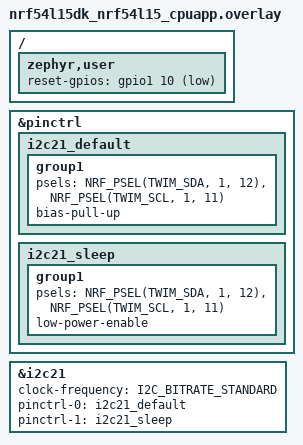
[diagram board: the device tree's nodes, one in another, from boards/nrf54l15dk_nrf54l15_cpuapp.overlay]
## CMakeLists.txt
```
cmake_minimum_required(VERSION 3.20.0)

find_package(Zephyr REQUIRED HINTS $ENV{ZEPHYR_BASE})
project(radar_central)

file(GLOB app_sources CONFIGURE_DEPENDS src/*.c)
target_sources(app PRIVATE ${app_sources})
target_include_directories(app PRIVATE include ../common)
```

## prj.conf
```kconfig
CONFIG_BT=y
CONFIG_BT_CENTRAL=y
CONFIG_BT_SMP=y
CONFIG_BT_BONDABLE=n
CONFIG_BT_CHANNEL_SOUNDING=y
CONFIG_BT_GAP_AUTO_UPDATE_CONN_PARAMS=n
CONFIG_BT_GATT_CLIENT=y
CONFIG_BT_GATT_AUTO_DISCOVER_CCC=y
CONFIG_BT_L2CAP_TX_MTU=498
CONFIG_BT_BUF_ACL_RX_SIZE=502
CONFIG_LOG=y
CONFIG_LOG_BUFFER_SIZE=8192
CONFIG_FPU=y
CONFIG_I2C=y
```

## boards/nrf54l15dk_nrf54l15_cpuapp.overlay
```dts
/*
 * NHD-1.69-160128UBC3 OLED (SSD1333), I2C mode:
 *   SCL  -> P1.11
 *   SDA  -> P1.12 (display SDAin + SDAout tied together on this pin)
 *   RES# -> P1.10 (shared with LED1)
 */

#include <zephyr/dt-bindings/gpio/gpio.h>
#include <zephyr/dt-bindings/pinctrl/nrf-pinctrl.h>
#include <zephyr/dt-bindings/i2c/i2c.h>

/ {
	zephyr,user {
		reset-gpios = <&gpio1 10 GPIO_ACTIVE_LOW>;
	};
};

&pinctrl {
	i2c21_default: i2c21_default {
		group1 {
			psels = <NRF_PSEL(TWIM_SDA, 1, 12)>,
				<NRF_PSEL(TWIM_SCL, 1, 11)>;
			bias-pull-up;
		};
	};

	i2c21_sleep: i2c21_sleep {
		group1 {
			psels = <NRF_PSEL(TWIM_SDA, 1, 12)>,
				<NRF_PSEL(TWIM_SCL, 1, 11)>;
			low-power-enable;
		};
	};
};

&i2c21 {
	status = "okay";
	clock-frequency = <I2C_BITRATE_STANDARD>;
	pinctrl-0 = <&i2c21_default>;
	pinctrl-1 = <&i2c21_sleep>;
	pinctrl-names = "default", "sleep";
};
```

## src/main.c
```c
#include "ble.h"

int main(void)
{
	int err = ble_init();

	if (err)
	{
		return err;
	}

	ble_initiator_run();

	return 0;
}
```

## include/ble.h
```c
#ifndef BLE_H_
#define BLE_H_

int ble_init(void);
void ble_initiator_run(void);

#endif
```

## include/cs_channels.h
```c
#ifndef CS_CHANNELS_H_
#define CS_CHANNELS_H_

#define CS_FIRST_CH           2
#define CS_N_CH               75
#define CS_FORBIDDEN_FIRST_CH 23
#define CS_FORBIDDEN_LAST_CH  25

#endif
```

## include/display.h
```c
#ifndef DISPLAY_H_
#define DISPLAY_H_

#include <stdint.h>

#include "font.h"

#define DISPLAY_W 160
#define DISPLAY_H 128

#define DISPLAY_BLACK 0x0000
#define DISPLAY_RED   0xF800
#define DISPLAY_WHITE 0xFFFF

#define DISPLAY_MAX_SCALE 2

#define DISPLAY_CHAR_W(scale) ((FONT_W + 1) * (scale))
#define DISPLAY_CHAR_H(scale) (FONT_H * (scale))

int display_init(void);
int display_rect(int x, int y, int w, int h, uint16_t color);
int display_text(int x, int y, const char *text, int scale, uint16_t fg, uint16_t bg);

#endif
```

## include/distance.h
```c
#ifndef DISTANCE_H_
#define DISTANCE_H_

#include "radar_svc.h"

void distance_reset(void);
void distance_process(const struct radar_iq_report *local, const struct radar_iq_report *peer);

#endif
```

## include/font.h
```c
#ifndef FONT_H_
#define FONT_H_

#include <stdint.h>

#define FONT_W 5
#define FONT_H 7

const uint8_t *font_glyph(char c);

#endif
```

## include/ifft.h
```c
#ifndef IFFT_H_
#define IFFT_H_

float ifft_estimate(const float *re, const float *im);

#endif
```

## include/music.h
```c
#ifndef MUSIC_H_
#define MUSIC_H_

float music_estimate(const float *re, const float *im, float d_min, float d_max);

#endif
```

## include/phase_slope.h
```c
#ifndef PHASE_SLOPE_H_
#define PHASE_SLOPE_H_

float phase_slope(const float *re, const float *im);

#endif
```

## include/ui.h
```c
#ifndef UI_H_
#define UI_H_

#include <stdbool.h>

void ui_show(int ps_cm, int ifft_cm, int music_cm, bool music_valid);

#endif
```

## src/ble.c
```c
#include <stddef.h>
#include <string.h>

#include <zephyr/kernel.h>
#include <zephyr/bluetooth/bluetooth.h>
#include <zephyr/bluetooth/conn.h>
#include <zephyr/bluetooth/cs.h>
#include <zephyr/bluetooth/gatt.h>
#include <zephyr/logging/log.h>

#include "ble.h"
#include "cs_channels.h"
#include "distance.h"
#include "radar_svc.h"

LOG_MODULE_REGISTER(ble, LOG_LEVEL_INF);

static const char target_name[] = "peripheral";

static struct bt_conn *conn;

#define CS_CONFIG_ID 0

K_SEM_DEFINE(sem_encrypted, 0, 1);
K_SEM_DEFINE(sem_cs, 0, 1);

static uint8_t cs_status;

static struct radar_iq_report local_report;

static void scan_start(void);

static bool name_match(struct bt_data *data, void *user_data)
{
	bool *found = user_data;

	if (data->type != BT_DATA_NAME_COMPLETE)
	{
		return true;
	}

	if (data->data_len == sizeof(target_name) - 1 &&
	    memcmp(data->data, target_name, data->data_len) == 0)
	{
		*found = true;
	}

	return false;
}

static void device_found(const bt_addr_le_t *addr, int8_t rssi, uint8_t type,
			 struct net_buf_simple *ad)
{
	char addr_str[BT_ADDR_LE_STR_LEN];
	bool found = false;
	int err;

	if (type != BT_GAP_ADV_TYPE_ADV_IND)
	{
		return;
	}

	bt_data_parse(ad, name_match, &found);

	if (!found)
	{
		return;
	}

	bt_addr_le_to_str(addr, addr_str, sizeof(addr_str));
	LOG_INF("Device found: %s (RSSI %d)", addr_str, rssi);

	if (bt_le_scan_stop())
	{
		return;
	}

	err = bt_conn_le_create(addr, BT_CONN_LE_CREATE_CONN, BT_LE_CONN_PARAM_DEFAULT, &conn);

	if (err)
	{
		LOG_ERR("Create connection failed (err %d)", err);
		scan_start();
	}
}

static void scan_start(void)
{
	int err = bt_le_scan_start(BT_LE_SCAN_PASSIVE, device_found);

	if (err)
	{
		LOG_ERR("Scanning failed to start (err %d)", err);
		return;
	}

	LOG_INF("Scanning started");
}

static void connected(struct bt_conn *c, uint8_t err)
{
	if (err)
	{
		LOG_ERR("Connection failed (err %u)", err);
		bt_conn_unref(conn);
		conn = NULL;
		return;
	}

	LOG_INF("Connected");
	local_report.count = 0;
	distance_reset();

	int ret = bt_conn_set_security(c, BT_SECURITY_L2);

	if (ret)
	{
		LOG_ERR("Set security failed (err %d)", ret);
	}
}

static void security_changed(struct bt_conn *c, bt_security_t level,
			     enum bt_security_err err)
{
	if (err)
	{
		LOG_ERR("Security failed (level %u, err %d)", level, err);
		bt_conn_disconnect(c, BT_HCI_ERR_REMOTE_USER_TERM_CONN);
		return;
	}

	LOG_INF("Security changed (level %u)", level);
	k_sem_give(&sem_encrypted);
}

static void cs_done(uint8_t status)
{
	cs_status = status;
	k_sem_give(&sem_cs);
}

static void cs_remote_capabilities(struct bt_conn *c, uint8_t status,
				   struct bt_conn_le_cs_capabilities *params)
{
	cs_done(status);
}

static void cs_config_complete(struct bt_conn *c, uint8_t status,
			       struct bt_conn_le_cs_config *config)
{
	cs_done(status);
}

static void cs_security_enable_complete(struct bt_conn *c, uint8_t status)
{
	cs_done(status);
}

static void cs_procedure_enable_complete(struct bt_conn *c, uint8_t status,
					 struct bt_conn_le_cs_procedure_enable_complete *params)
{
	cs_done(status);
}

static bool cs_step_collect(struct bt_le_cs_subevent_step *step, void *user_data)
{
	if (step->mode != BT_HCI_OP_LE_CS_MAIN_MODE_2 || local_report.count >= RADAR_MAX_CHANNELS)
	{
		return true;
	}

	const struct bt_hci_le_cs_step_data_mode_2 *data = (const void *)step->data;
	struct bt_le_cs_iq_sample iq = bt_le_cs_parse_pct(data->tone_info[0].phase_correction_term);

	local_report.iq[local_report.count].channel = step->channel;
	local_report.iq[local_report.count].i = iq.i;
	local_report.iq[local_report.count].q = iq.q;
	local_report.iq[local_report.count].quality = data->tone_info[0].quality_indicator;
	local_report.count++;

	return true;
}

static void cs_subevent_result(struct bt_conn *c, struct bt_conn_le_cs_subevent_result *result)
{
	if (result->header.procedure_counter != local_report.procedure_counter)
	{
		local_report.procedure_counter = result->header.procedure_counter;
		local_report.count = 0;
	}

	if (result->step_data_buf)
	{
		bt_le_cs_step_data_parse(result->step_data_buf, cs_step_collect, NULL);
	}

	if (result->header.procedure_done_status == BT_CONN_LE_CS_PROCEDURE_ABORTED)
	{
		LOG_WRN("Procedure %u aborted", local_report.procedure_counter);
		local_report.count = 0;
	}
}

static void disconnected(struct bt_conn *c, uint8_t reason)
{
	LOG_INF("Disconnected (reason %u)", reason);
	bt_conn_unref(conn);
	conn = NULL;
}

static void recycled(void)
{
	scan_start();
}

BT_CONN_CB_DEFINE(conn_callbacks) =
{
	.connected = connected,
	.disconnected = disconnected,
	.recycled = recycled,
	.security_changed = security_changed,
	.le_cs_read_remote_capabilities_complete = cs_remote_capabilities,
	.le_cs_config_complete = cs_config_complete,
	.le_cs_security_enable_complete = cs_security_enable_complete,
	.le_cs_procedure_enable_complete = cs_procedure_enable_complete,
	.le_cs_subevent_data_available = cs_subevent_result,
};

int ble_init(void)
{
	int err = bt_enable(NULL);

	if (err)
	{
		LOG_ERR("Bluetooth init failed (err %d)", err);
		return err;
	}

	scan_start();
	return 0;
}

static int cs_wait(const char *step)
{
	if (k_sem_take(&sem_cs, K_SECONDS(5)))
	{
		LOG_ERR("%s timed out", step);
		return -ETIMEDOUT;
	}

	if (cs_status)
	{
		LOG_ERR("%s failed (status 0x%02x)", step, cs_status);
		return -EIO;
	}

	LOG_INF("%s done", step);
	return 0;
}

static int cs_setup(void)
{
	const struct bt_le_cs_set_default_settings_param settings =
	{
		.enable_initiator_role = true,
		.enable_reflector_role = false,
		.cs_sync_antenna_selection = BT_LE_CS_ANTENNA_SELECTION_OPT_REPETITIVE,
		.max_tx_power = BT_HCI_OP_LE_CS_MAX_MAX_TX_POWER,
	};

	struct bt_le_cs_create_config_params config =
	{
		.id = CS_CONFIG_ID,
		.mode = BT_CONN_LE_CS_MAIN_MODE_2_NO_SUB_MODE,
		.min_main_mode_steps = 2,
		.max_main_mode_steps = 10,
		.main_mode_repetition = 0,
		.mode_0_steps = 3,
		.role = BT_CONN_LE_CS_ROLE_INITIATOR,
		.rtt_type = BT_CONN_LE_CS_RTT_TYPE_AA_ONLY,
		.cs_sync_phy = BT_CONN_LE_CS_SYNC_1M_PHY,
		.channel_map_repetition = 1,
		.channel_selection_type = BT_CONN_LE_CS_CHSEL_TYPE_3B,
	};

	for (uint8_t ch = CS_FIRST_CH; ch < CS_FIRST_CH + CS_N_CH; ch++)
	{
		if (ch >= CS_FORBIDDEN_FIRST_CH && ch <= CS_FORBIDDEN_LAST_CH)
		{
			continue;
		}

		BT_LE_CS_CHANNEL_BIT_SET_VAL(config.channel_map, ch, 1);
	}

	int err = bt_le_cs_set_default_settings(conn, &settings);

	if (err)
	{
		LOG_ERR("CS default settings failed (err %d)", err);
		return err;
	}

	err = bt_le_cs_read_remote_supported_capabilities(conn);

	if (err)
	{
		LOG_ERR("CS read remote capabilities failed (err %d)", err);
		return err;
	}

	err = cs_wait("CS remote capabilities");

	if (err)
	{
		return err;
	}

	err = bt_le_cs_create_config(conn, &config, BT_LE_CS_CREATE_CONFIG_CONTEXT_LOCAL_AND_REMOTE);

	if (err)
	{
		LOG_ERR("CS create config failed (err %d)", err);
		return err;
	}

	err = cs_wait("CS config");

	if (err)
	{
		return err;
	}

	err = bt_le_cs_security_enable(conn);

	if (err)
	{
		LOG_ERR("CS security enable failed (err %d)", err);
		return err;
	}

	err = cs_wait("CS security");

	if (err)
	{
		return err;
	}

	const struct bt_le_cs_set_procedure_parameters_param procedure =
	{
		.config_id = CS_CONFIG_ID,
		.max_procedure_len = 1600,
		.min_procedure_interval = 10,
		.max_procedure_interval = 10,
		.max_procedure_count = 0,
		.min_subevent_len = 50000,
		.max_subevent_len = 50000,
		.tone_antenna_config_selection = BT_LE_CS_TONE_ANTENNA_CONFIGURATION_A1_B1,
		.phy = BT_LE_CS_PROCEDURE_PHY_1M,
		.tx_power_delta = 0x80,
		.preferred_peer_antenna = BT_LE_CS_PROCEDURE_PREFERRED_PEER_ANTENNA_1,
		.snr_control_initiator = BT_LE_CS_SNR_CONTROL_NOT_USED,
		.snr_control_reflector = BT_LE_CS_SNR_CONTROL_NOT_USED,
	};

	err = bt_le_cs_set_procedure_parameters(conn, &procedure);

	if (err)
	{
		LOG_ERR("CS procedure parameters failed (err %d)", err);
		return err;
	}

	const struct bt_le_cs_procedure_enable_param enable =
	{
		.config_id = CS_CONFIG_ID,
		.enable = 1,
	};

	err = bt_le_cs_procedure_enable(conn, &enable);

	if (err)
	{
		LOG_ERR("CS procedure enable failed (err %d)", err);
		return err;
	}

	return cs_wait("CS procedure enable");
}

static uint16_t iq_value_handle;

static void mtu_exchanged(struct bt_conn *c, uint8_t err, struct bt_gatt_exchange_params *params)
{
	cs_done(err);
}

static uint8_t iq_discovered(struct bt_conn *c, const struct bt_gatt_attr *attr,
			     struct bt_gatt_discover_params *params)
{
	if (!attr)
	{
		cs_done(BT_ATT_ERR_ATTRIBUTE_NOT_FOUND);
		return BT_GATT_ITER_STOP;
	}

	const struct bt_gatt_chrc *chrc = attr->user_data;

	iq_value_handle = chrc->value_handle;
	cs_done(0);
	return BT_GATT_ITER_STOP;
}

static uint8_t iq_notified(struct bt_conn *c, struct bt_gatt_subscribe_params *params,
			   const void *data, uint16_t length)
{
	if (!data)
	{
		LOG_INF("IQ unsubscribed");
		return BT_GATT_ITER_STOP;
	}

	const struct radar_iq_report *peer = data;
	size_t header = offsetof(struct radar_iq_report, iq);

	if (length < header || peer->count > RADAR_MAX_CHANNELS ||
	    length < header + peer->count * sizeof(struct radar_iq))
	{
		LOG_ERR("IQ invalid length %u", length);
		return BT_GATT_ITER_CONTINUE;
	}

	if (peer->procedure_counter != local_report.procedure_counter)
	{
		LOG_WRN("IQ procedure mismatch (local %u, peer %u)",
			local_report.procedure_counter, peer->procedure_counter);
		return BT_GATT_ITER_CONTINUE;
	}

	distance_process(&local_report, peer);
	return BT_GATT_ITER_CONTINUE;
}

static void iq_subscribed(struct bt_conn *c, uint8_t err, struct bt_gatt_subscribe_params *params)
{
	cs_done(err);
}

static int gatt_setup(void)
{
	static struct bt_gatt_exchange_params mtu_params =
	{
		.func = mtu_exchanged,
	};

	static struct bt_gatt_discover_params discover_params =
	{
		.func = iq_discovered,
		.start_handle = BT_ATT_FIRST_ATTRIBUTE_HANDLE,
		.end_handle = BT_ATT_LAST_ATTRIBUTE_HANDLE,
		.type = BT_GATT_DISCOVER_CHARACTERISTIC,
	};

	static struct bt_gatt_discover_params ccc_discover_params;

	static struct bt_gatt_subscribe_params subscribe_params =
	{
		.notify = iq_notified,
		.subscribe = iq_subscribed,
		.value = BT_GATT_CCC_NOTIFY,
		.end_handle = BT_ATT_LAST_ATTRIBUTE_HANDLE,
		.disc_params = &ccc_discover_params,
	};

	int err = bt_gatt_exchange_mtu(conn, &mtu_params);

	if (err)
	{
		LOG_ERR("MTU exchange failed (err %d)", err);
		return err;
	}

	err = cs_wait("MTU exchange");

	if (err)
	{
		return err;
	}

	LOG_INF("MTU %u", bt_gatt_get_mtu(conn));

	discover_params.uuid = RADAR_IQ_UUID;
	err = bt_gatt_discover(conn, &discover_params);

	if (err)
	{
		LOG_ERR("IQ discovery failed (err %d)", err);
		return err;
	}

	err = cs_wait("IQ discovery");

	if (err)
	{
		return err;
	}

	LOG_INF("IQ value handle 0x%04x", iq_value_handle);

	subscribe_params.value_handle = iq_value_handle;
	subscribe_params.ccc_handle = BT_GATT_AUTO_DISCOVER_CCC_HANDLE;
	err = bt_gatt_subscribe(conn, &subscribe_params);

	if (err)
	{
		LOG_ERR("IQ subscribe failed (err %d)", err);
		return err;
	}

	return cs_wait("IQ subscribe");
}

void ble_initiator_run(void)
{
	while (true)
	{
		k_sem_take(&sem_encrypted, K_FOREVER);

		if (gatt_setup() || cs_setup())
		{
			bt_conn_disconnect(conn, BT_HCI_ERR_REMOTE_USER_TERM_CONN);
		}
	}
}
```

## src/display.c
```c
#include <stdbool.h>
#include <string.h>

#include <zephyr/device.h>
#include <zephyr/devicetree.h>
#include <zephyr/drivers/gpio.h>
#include <zephyr/drivers/i2c.h>
#include <zephyr/kernel.h>
#include <zephyr/logging/log.h>
#include <zephyr/sys/util.h>

#include "display.h"
#include "font.h"

LOG_MODULE_REGISTER(display, LOG_LEVEL_INF);

#define SSD1333_ADDR  0x3C
#define I2C_CTRL_CMD  0x00
#define I2C_CTRL_DATA 0x40
#define I2C_CHUNK     64
#define I2C_RETRIES   3
#define COL_OFFSET    8

static const struct device *i2c_dev = DEVICE_DT_GET(DT_NODELABEL(i2c21));
static const struct gpio_dt_spec reset_gpio = GPIO_DT_SPEC_GET(DT_PATH(zephyr_user), reset_gpios);

static int i2c_write_retry(const uint8_t *buf, size_t len)
{
	int err = 0;

	for (int attempt = 0; attempt < I2C_RETRIES; attempt++)
	{
		err = i2c_write(i2c_dev, buf, len, SSD1333_ADDR);

		if (!err)
		{
			return 0;
		}

		i2c_recover_bus(i2c_dev);
		k_msleep(2);
	}

	return err;
}

static int write_data(const uint8_t *data, size_t len)
{
	uint8_t buf[1 + I2C_CHUNK];

	while (len > 0)
	{
		size_t chunk = MIN(len, I2C_CHUNK);

		buf[0] = I2C_CTRL_DATA;
		memcpy(&buf[1], data, chunk);

		int err = i2c_write_retry(buf, chunk + 1);

		if (err)
		{
			return err;
		}

		data += chunk;
		len -= chunk;
	}

	return 0;
}

static int write_cmd(const uint8_t *cmd, size_t len)
{
	uint8_t buf[2] = {I2C_CTRL_CMD, cmd[0]};
	int err = i2c_write_retry(buf, sizeof(buf));

	if (err)
	{
		return err;
	}

	return write_data(&cmd[1], len - 1);
}

static int display_reset(void)
{
	if (!device_is_ready(i2c_dev))
	{
		LOG_ERR("I2C bus not ready");
		return -ENODEV;
	}

	if (!gpio_is_ready_dt(&reset_gpio))
	{
		LOG_ERR("Reset GPIO not ready");
		return -ENODEV;
	}

	int err = gpio_pin_configure_dt(&reset_gpio, GPIO_OUTPUT_ACTIVE);

	if (err)
	{
		LOG_ERR("Reset GPIO configure failed (err %d)", err);
		return err;
	}

	k_msleep(10);
	gpio_pin_set_dt(&reset_gpio, 0);
	k_msleep(100);

	return 0;
}

static int set_window(int x, int y, int w, int h)
{
	if (x < 0 || y < 0 || w <= 0 || h <= 0 || x + w > DISPLAY_W || y + h > DISPLAY_H)
	{
		return -EINVAL;
	}

	const uint8_t col_addr[] = {0x15, COL_OFFSET + x, COL_OFFSET + x + w - 1};
	const uint8_t row_addr[] = {0x75, y, y + h - 1};
	const uint8_t write_ram[] = {0x5C};

	int err = write_cmd(col_addr, sizeof(col_addr));

	if (!err)
	{
		err = write_cmd(row_addr, sizeof(row_addr));
	}

	if (!err)
	{
		err = write_cmd(write_ram, sizeof(write_ram));
	}

	return err;
}

int display_rect(int x, int y, int w, int h, uint16_t color)
{
	static uint8_t line[DISPLAY_W * 2];

	int err = set_window(x, y, w, h);

	if (err)
	{
		return err;
	}

	for (int i = 0; i < w; i++)
	{
		line[2 * i] = color >> 8;
		line[2 * i + 1] = color & 0xFF;
	}

	for (int row = 0; row < h; row++)
	{
		err = write_data(line, w * 2);

		if (err)
		{
			return err;
		}
	}

	return 0;
}

static int draw_char(int x, int y, char c, int scale, uint16_t fg, uint16_t bg)
{
	static uint8_t pixels[DISPLAY_CHAR_W(DISPLAY_MAX_SCALE) * DISPLAY_CHAR_H(DISPLAY_MAX_SCALE) * 2];
	const uint8_t *glyph = font_glyph(c);
	int w = DISPLAY_CHAR_W(scale);
	int h = DISPLAY_CHAR_H(scale);

	for (int py = 0; py < h; py++)
	{
		uint8_t row = glyph ? glyph[py / scale] : 0;

		for (int px = 0; px < w; px++)
		{
			int col = px / scale;
			bool on = col < FONT_W && ((row >> (FONT_W - 1 - col)) & 1);
			uint16_t color = on ? fg : bg;
			int i = 2 * (py * w + px);

			pixels[i] = color >> 8;
			pixels[i + 1] = color & 0xFF;
		}
	}

	int err = set_window(x, y, w, h);

	if (err)
	{
		return err;
	}

	return write_data(pixels, w * h * 2);
}

int display_text(int x, int y, const char *text, int scale, uint16_t fg, uint16_t bg)
{
	if (scale < 1 || scale > DISPLAY_MAX_SCALE)
	{
		return -EINVAL;
	}

	for (; *text; text++, x += DISPLAY_CHAR_W(scale))
	{
		int err = draw_char(x, y, *text, scale, fg, bg);

		if (err)
		{
			return err;
		}
	}

	return 0;
}

int display_init(void)
{
	static const uint8_t unlock[]        = {0xFD, 0x12};
	static const uint8_t display_off[]   = {0xAE};
	static const uint8_t remap[]         = {0xA0, 0x74};
	static const uint8_t start_line[]    = {0xA1, 0x00};
	static const uint8_t offset[]        = {0xA2, 0x30};
	static const uint8_t normal[]        = {0xA6};
	static const uint8_t phase_length[]  = {0xB1, 0x22};
	static const uint8_t display_clock[] = {0xB3, 0xD1};
	static const uint8_t contrast[]      = {0xC1, 0x45, 0x43, 0x90};
	static const uint8_t mux_ratio[]     = {0xCA, 0x7F};
	static const uint8_t display_on[]    = {0xAF};

	static const struct
	{
		const uint8_t *cmd;
		size_t len;
	} seq[] =
	{
		{unlock, sizeof(unlock)},
		{display_off, sizeof(display_off)},
		{remap, sizeof(remap)},
		{start_line, sizeof(start_line)},
		{offset, sizeof(offset)},
		{normal, sizeof(normal)},
		{phase_length, sizeof(phase_length)},
		{display_clock, sizeof(display_clock)},
		{contrast, sizeof(contrast)},
		{mux_ratio, sizeof(mux_ratio)},
		{display_on, sizeof(display_on)},
	};

	int err = display_reset();

	if (err)
	{
		return err;
	}

	for (size_t i = 0; i < ARRAY_SIZE(seq); i++)
	{
		err = write_cmd(seq[i].cmd, seq[i].len);

		if (err)
		{
			LOG_ERR("Init command 0x%02x failed (err %d)", seq[i].cmd[0], err);
			return err;
		}
	}

	err = display_rect(0, 0, DISPLAY_W, DISPLAY_H, DISPLAY_BLACK);

	if (err)
	{
		LOG_ERR("Clear failed (err %d)", err);
		return err;
	}

	LOG_INF("Display initialized");
	return 0;
}
```

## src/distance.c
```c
#include <math.h>

#include <zephyr/bluetooth/hci_types.h>
#include <zephyr/kernel.h>
#include <zephyr/logging/log.h>
#include <zephyr/sys/atomic.h>

#include "cs_channels.h"
#include "distance.h"
#include "ifft.h"
#include "music.h"
#include "phase_slope.h"
#include "ui.h"

LOG_MODULE_REGISTER(distance, LOG_LEVEL_INF);

#define AVG_N 10

#define MUSIC_BEFORE 4.0f
#define MUSIC_AFTER  2.0f

#define DISTANCE_STACK_SIZE 3072
#define DISTANCE_PRIORITY   10

struct reports
{
	struct radar_iq_report local;
	struct radar_iq_report peer;
};

K_MSGQ_DEFINE(distance_msgq, sizeof(struct reports), 1, 1);

static atomic_t reset_req;

static float ps_hist[AVG_N];
static float ifft_hist[AVG_N];
static float music_hist[AVG_N];
static uint8_t avg_pos;
static uint8_t avg_count;

static int mean_std(const float *v, float *mean, float *std)
{
	float sum = 0.0f;
	int count = 0;

	for (int n = 0; n < AVG_N; n++)
	{
		if (!isnan(v[n]))
		{
			sum += v[n];
			count++;
		}
	}

	if (count == 0)
	{
		return 0;
	}

	*mean = sum / count;

	float sq = 0.0f;

	for (int n = 0; n < AVG_N; n++)
	{
		if (!isnan(v[n]))
		{
			float dv = v[n] - *mean;

			sq += dv * dv;
		}
	}

	*std = sqrtf(sq / count);

	return count;
}

static const struct radar_iq *iq_find(const struct radar_iq_report *report, uint8_t channel)
{
	for (uint8_t n = 0; n < report->count; n++)
	{
		if (report->iq[n].channel == channel)
		{
			return &report->iq[n];
		}
	}

	return NULL;
}

void distance_reset(void)
{
	k_msgq_purge(&distance_msgq);
	atomic_set(&reset_req, 1);
}

static void process(const struct radar_iq_report *local, const struct radar_iq_report *peer)
{
	float re[CS_N_CH] = {0};
	float im[CS_N_CH] = {0};
	uint8_t valid = 0;

	for (uint8_t n = 0; n < local->count; n++)
	{
		const struct radar_iq *c = &local->iq[n];
		const struct radar_iq *p = iq_find(peer, c->channel);
		int k = c->channel - CS_FIRST_CH;

		if (!p || c->quality != BT_HCI_LE_CS_TONE_QUALITY_HIGH ||
		    p->quality != BT_HCI_LE_CS_TONE_QUALITY_HIGH || k < 0 || k >= CS_N_CH)
		{
			continue;
		}

		re[k] = c->i * p->i - c->q * p->q;
		im[k] = c->i * p->q + c->q * p->i;
		valid++;
	}

    float d_ps = phase_slope(re, im);
	
    if (isnan(d_ps))
	{
		LOG_WRN("Procedure %u: too few valid channels (%u)", peer->procedure_counter, valid);
		return;
	}
	
	float d_ifft = ifft_estimate(re, im);
	float d_music = music_estimate(re, im, d_ifft - MUSIC_BEFORE, d_ifft + MUSIC_AFTER);

	ps_hist[avg_pos] = d_ps;
	ifft_hist[avg_pos] = d_ifft;
	music_hist[avg_pos] = d_music;
	avg_pos = (avg_pos + 1) % AVG_N;

	if (avg_count < AVG_N)
	{
		avg_count++;
	}

	if (avg_count < AVG_N)
	{
		return;
	}

	float ps_mean = 0.0f, ps_std = 0.0f;
	float ifft_mean = 0.0f, ifft_std = 0.0f;
	float music_mean = 0.0f, music_std = 0.0f;

	mean_std(ps_hist, &ps_mean, &ps_std);
	mean_std(ifft_hist, &ifft_mean, &ifft_std);
	int music_n = mean_std(music_hist, &music_mean, &music_std);

	ui_show((int)(ps_mean * 100.0f), (int)(ifft_mean * 100.0f), (int)(music_mean * 100.0f),
		music_n > 0);

	if (music_n == 0)
	{
		LOG_INF("Avg PS %d cm (std %d cm), IFFT %d cm (std %d cm), MUSIC n/a",
			(int)(ps_mean * 100.0f), (int)(ps_std * 100.0f),
			(int)(ifft_mean * 100.0f), (int)(ifft_std * 100.0f));
		return;
	}

	LOG_INF("Avg PS %d cm (std %d cm), IFFT %d cm (std %d cm), MUSIC %d cm (std %d cm)",
		(int)(ps_mean * 100.0f), (int)(ps_std * 100.0f),
		(int)(ifft_mean * 100.0f), (int)(ifft_std * 100.0f),
		(int)(music_mean * 100.0f), (int)(music_std * 100.0f));
}

static void distance_thread(void *p1, void *p2, void *p3)
{
	static struct reports r;

	while (true)
	{
		k_msgq_get(&distance_msgq, &r, K_FOREVER);

		if (atomic_clear(&reset_req))
		{
			avg_pos = 0;
			avg_count = 0;
		}

		process(&r.local, &r.peer);
	}
}

K_THREAD_DEFINE(distance_tid, DISTANCE_STACK_SIZE, distance_thread, NULL, NULL, NULL,
		DISTANCE_PRIORITY, 0, 0);

void distance_process(const struct radar_iq_report *local, const struct radar_iq_report *peer)
{
	static struct reports r;

	r.local = *local;
	r.peer = *peer;

	k_msgq_purge(&distance_msgq);
	k_msgq_put(&distance_msgq, &r, K_NO_WAIT);
}
```
